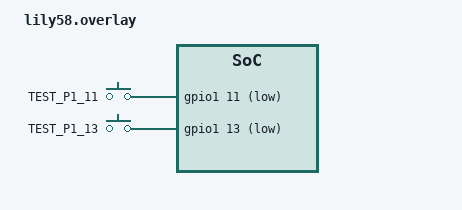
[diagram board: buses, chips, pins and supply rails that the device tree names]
/ {
    buttons {
        compatible = "gpio-keys";

        test_p1_11: button_1 {
            label = "TEST_P1_11";
            gpios = <&gpio1 11 GPIO_ACTIVE_LOW>;
        };

        test_p1_13: button_2 {
            label = "TEST_P1_13";
            gpios = <&gpio1 13 GPIO_ACTIVE_LOW>;
        };
    };
};
